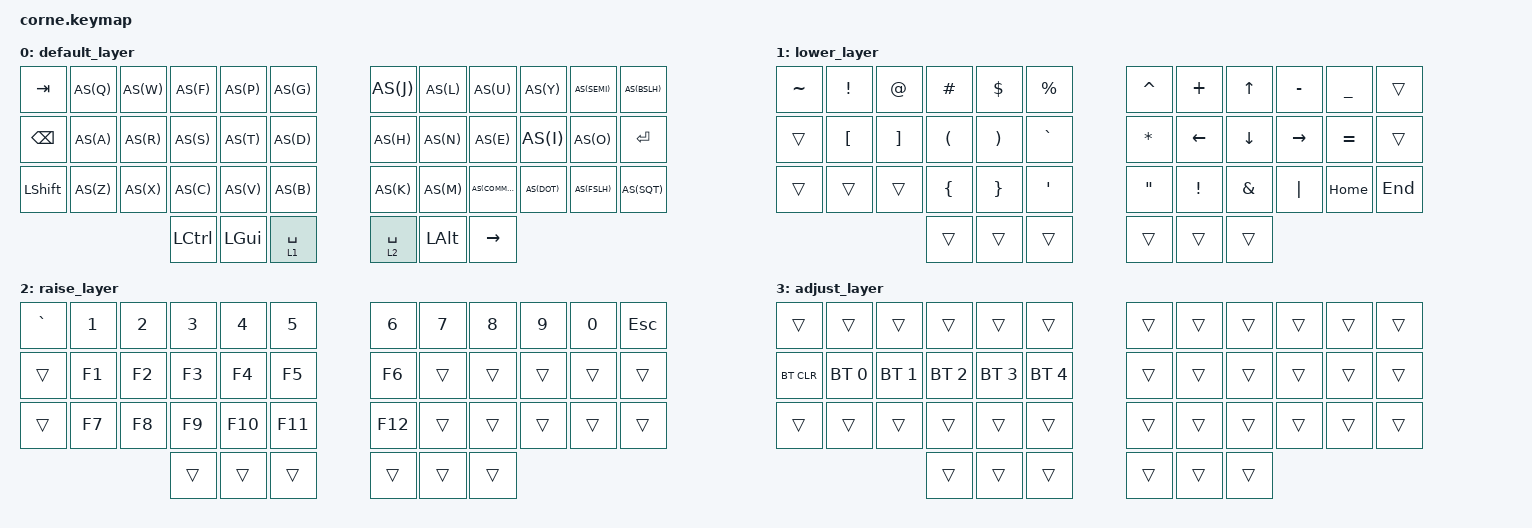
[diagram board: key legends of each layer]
/*
 * Copyright (c) 2020 The ZMK Contributors
 *
 * SPDX-License-Identifier: MIT
 */

#include <behaviors.dtsi>
#include <dt-bindings/zmk/keys.h>
#include <dt-bindings/zmk/bt.h>

#define AS(keycode) &as LS(keycode) keycode     // Autoshift Macro


/ {
        behaviors {
            as: auto_shift {
                compatible = "zmk,behavior-hold-tap";
                label = "AUTO_SHIFT";
                #binding-cells = <2>;
                tapping_term_ms = <175>;
                quick_tap_ms = <0>;
                flavor = "tap-preferred";
                bindings = <&kp>, <&kp>;
            };
        };

        keymap {
                compatible = "zmk,keymap";

                default_layer {
// -----------------------------------------------------------------------------------------
// |  TAB |  Q  |  W  |  F  |  P  |  G  |   |  J  |  L   |  U  |  Y  | SCLN  | BSLH |
// | BSPC |  A  |  R  |  S  |  T  |  D  |   |  H  |  N   |  E  |  I  |  O  |  ENT   |
// | SHFT |  Z  |  X  |  C  |  V  |  B  |   |  K  |  M   |  ,  |  .  |  /  | QUOT  |
//                    | LCTRL | LGUI | 1 |   | 2 | LALT  | RIGHT |
                        bindings = <
   &kp TAB   AS(Q) AS(W) AS(F) AS(P) AS(G)   AS(J) AS(L)  AS(U)     AS(Y)   AS(SEMI) AS(BSLH)
   &kp BSPC  AS(A) AS(R) AS(S) AS(T) AS(D)   AS(H) AS(N)  AS(E)     AS(I)   AS(O)    &kp ENTER
   &kp LSHFT AS(Z) AS(X) AS(C) AS(V) AS(B)   AS(K) AS(M)  AS(COMMA) AS(DOT) AS(FSLH) AS(SQT)
                  &kp LCTRL &kp LGUI &lt 1 SPACE    &lt 2 SPACE &kp LALT &kp RIGHT
                        >;
                };
                lower_layer {
// -----------------------------------------------------------------------------------------
// |   ~  |   !  |   @  |   #  |   $  |   %  |   ^  |   +  |  UP  |   -  |   _  |      |
// |------+------+------+------+------+------+------+------+------+------+------+------|
// |      |  [   |  ]   |  (   |  )   |  `   |  *   | LEFT | DOWN | RIGHT|   =  | ARROW|
// |------+------+------+------+------+------+------+------+------+------+------+------|
// |      |      |      |  {   |  }   |   '  |  "   |   !  |  &   |  |   | HOME | END  |
// |------+------+------+------+------+------+------+------+------+------+------+------|
//               |      |      |      |             |      |      |      |
                        bindings = <
   &kp TILDE &kp EXCL &kp AT   &kp HASH &kp DLLR &kp PRCNT      &kp CARET &kp PLUS  &kp UP   &kp MINUS  &kp UNDER &trans
   &trans    &kp LBKT &kp RBKT &kp LPAR &kp RPAR &kp GRAVE      &kp STAR  &kp LEFT  &kp DOWN &kp RIGHT  &kp EQUAL &trans
   &trans    &trans   &trans   &kp LBRC &kp RBRC &kp APOS       &kp DQT   &kp EXCL  &kp AMPS &kp PIPE   &kp HOME  &kp END
                    &trans     &trans       &trans      &trans  &trans   &trans
                        >;
                };

                raise_layer {
/* Raise
 * ,-----------------------------------------------------------------------------------.
 * |   `  |   1  |   2  |   3  |   4  |   5  |   6  |   7  |   8  |   9  |   0  | ESC  |
 * |------+------+------+------+------+------+------+------+------+------+------+------|
 * |      |  F1  |  F2  |  F3  |  F4  |  F5  |  F6  |      |      |      |      |      |
 * |------+------+------+------+------+------+------+------+------+------+------+------|
 * |      |  F7  |  F8  |  F9  |  F10 |  F11 |  F12 |      |      |      |      |      |
 * |------+------+------+------+------+------+------+------+------+------+------+------|
 * |      |      |      |      |      |      |      |      |      |      |      |      |
 * `-----------------------------------------------------------------------------------'
 */
                        bindings = <
   &kp GRAVE &kp N1 &kp N2 &kp N3 &kp N4  &kp N5   &kp N6  &kp N7 &kp N8 &kp N9 &kp N0 &kp ESC
   &trans    &kp F1 &kp F2 &kp F3 &kp F4  &kp F5   &kp F6  &trans &trans &trans &trans &trans
   &trans    &kp F7 &kp F8 &kp F9 &kp F10 &kp F11  &kp F12 &trans &trans &trans &trans &trans
                    	     &trans &trans   &trans   &trans   &trans    &trans
                        >;
                };

                adjust_layer {

/* adjust
 * ,-----------------------------------------------------------------------------------.
 * |      |      |      |      |      |      |      |      |      |      |      |      |
 * |------+------+------+------+------+------+------+------+------+------+------+------|
 * | BT_CTRL | BT_1 | BT_2 | BT_3 | BT_4 | BT_5 |       |      |      |      |      |
 * |------+------+------+------+------+------+------+------+------+------+------+------|
 * |      |      |      |      |      |      |      |      |      |      |      |      |
 * |------+------+------+------+------+------+------+------+------+------+------+------|
 * |      |      |      |      |      |      |      |      |      |      |      |      |
 * `-----------------------------------------------------------------------------------'
 */
                        bindings = <
   &trans     &trans       &trans       &trans       &trans       &trans            &trans &trans &trans &trans &trans &trans
   &bt BT_CLR &bt BT_SEL 0 &bt BT_SEL 1 &bt BT_SEL 2 &bt BT_SEL 3 &bt BT_SEL 4      &trans &trans &trans &trans &trans &trans
   &trans     &trans       &trans       &trans       &trans       &trans            &trans &trans &trans &trans &trans &trans
                    	    &trans  &trans  &trans         &trans  &trans  &trans
                        >;
                };
        };
};

/ {
    conditional_layers {
        compatible = "zmk,conditional-layers";
        tri_layer {
            if-layers = <1 2>;
            then-layer = <3>;
        };
    };
};
